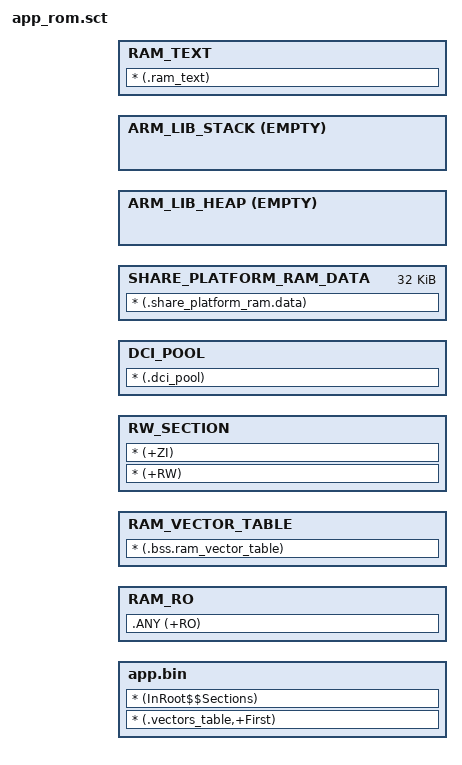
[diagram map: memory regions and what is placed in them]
#!armclang --target=arm-arm-none-eabi -march=armv8-m.main -E -x c
#include "..\..\..\boot\ap_boot\inc\rom_defines.h"
#include ".\inc\mem_config.h"
#include ".\inc\mem_cfg_int.h"
#include "..\..\..\..\kernel\logging\inc\rtl87x3k\trace_file_address.h"
; *************************************************************
; *** Scatter-Loading Description File generated by uVision ***
; *************************************************************

#define RW_SECTION_SIZE   DATA_RAM_VECTOR_TABLE_SIZE
#define RW_SECTION_ADR    DATA_RAM_VECTOR_TABLE_ADDR

#define LOAD_ROM_ADDRESS                  BOOT_ROM_ADDRESS
#define LOAD_ROM_SIZE                     BOOT_ROM_SIZE

#define SHARE_PLATFORM_RAM_DATA_ADDR    SHARED_SRAM_BASE
#define SHARE_PLATFORM_RAM_DATA_SIZE    (32 * 1024)

#define Stack_Size                   CODE_RAM_MAIN_STACK_SIZE

#define Stack_Addr                   CODE_RAM_MAIN_STACK_START_ADDR

#define Heap_Size                    DATA_HEAP_SIZE

#define Heap_Addr                    DATA_HEAP_ADDR

;LOAD_BUFFER_RAM EXT0_ADDR EXT0_SIZE
;{
;    TEST_BUFFER_DATA +0
;    {
;        * (.ram.buffer)
;    }
;}

;LOAD_DATA_RAM0 DATA_SRAM0_ADDR DATA_SRAM0_SIZE
;{

;    TEST_DATA_RAM0 +0
;    {
;        * (.ram.data0)
;    }
;}

;LOAD_DATA_RAM1 DATA_SRAM1_ADDR DATA_SRAM1_SIZE
;{

;    TEST_DATA_RAM1 +0
;    {
;        * (.ram.data1)
;    }

;}

LOAD_ITCM0 LOAD_ROM_ADDRESS LOAD_ROM_SIZE
{   

    app.bin LOAD_ROM_ADDRESS
    {
        * (.vectors_table,+First)
;        * (RESET)
        * (InRoot$$Sections)
	}	
	
;    OS  +0
;    {
;        startup_rtl8762c.o
;        system_rtl8762c.o
;        rtl8762c_platform.o
;        croutine.o
;        event_groups.o
;        list.o
;        queue.o
;        tasks.o
;        timers.o
;        port.o
;    }
    
    RAM_RO +0 ALIGN 4
    {
        .ANY (+RO)   
    }

	RAM_VECTOR_TABLE RW_SECTION_ADR ALIGN 128
	{
		* (.bss.ram_vector_table)
	}
	
	RW_SECTION +0
	{
		* (+RW)
        * (+ZI)
	}
	ScatterAssert((ImageLength(RAM_VECTOR_TABLE) + ImageLength(RW_SECTION)) < RW_SECTION_SIZE)

    ; DCI test framebuffer pool. Its own execution region on purpose: left inside
    ; RW_SECTION the ScatterAssert above rejects it, since one 160x120 RGB565 frame is
    ; 38432 B against a 10 KB budget. Sits between RW_SECTION and the heap, which starts
    ; after it because DATA_HEAP_ADDR is derived from DCI_POOL_ADDR + DCI_POOL_SIZE.
    DCI_POOL DCI_POOL_ADDR DCI_POOL_SIZE
    {
        * (.dci_pool)
    }

    SHARE_PLATFORM_RAM_DATA SHARE_PLATFORM_RAM_DATA_ADDR SHARE_PLATFORM_RAM_DATA_SIZE
    {
        * (.share_platform_ram.data)
    }

    ARM_LIB_HEAP Heap_Addr EMPTY Heap_Size
    {    ; Heap region growing up
    }

    ARM_LIB_STACK Stack_Addr + Stack_Size EMPTY -Stack_Size 
    { ; Stack region growing down
    }

	RAM_TEXT CODE_RAM_TEXT_ADDR CODE_RAM_TEXT_SIZE
    {
        * (.ram_text)
    }
	
}

;LOAD_DTCM1 DTCM1_RAM_TEXT_ADR DTCM1_RAM_TEXT_SIZE
;{
;    RAM_RO1.bin +0
;    {
;        .ANY (+RO)   
;    }
;}

;LOAD_SHARE_RAM DSP_SHM_ADDR DSP_SHM_SIZE
;{
;    TEST_SHARE_DATA +0
;    {
;        * (.ram.share.data)
;    }
;}
;LOAD_ROM_NP_TRACE ROM_NP_TRACE_START ROM_NP_TRACE_SIZE
;{
;    app_ap.trace +0
;    {
;        * (.TRACE_HEADER, +First)
;        * (.TRACE)
;    }
;}
;LOAD_LOG_MODULE_TRACE 0xffff0000
;{
;    app_ap_log_module_config.trace 0xffff0000
;    {
;        * (.log_module_header, +First)
;        * (.log_module)
;    }
;}


